# BB2D register map
Vendor: Texas Instruments
Peripheral module from a debugger description file (folder DRA74xP_75xP_76xP_77xP).
Registers are 32-bit, read-only, reset 0x0 unless marked. A register's access mark holds for its fields unless they carry their own. Offsets are as the file gives them; lines under a group give offsets from that group; [hi:lo] are bit positions; {n}, {i} and the like mark numbered series; 'fields as' and 'values as' point back to an identical list; <NAME> marks a mode.

## BB2D
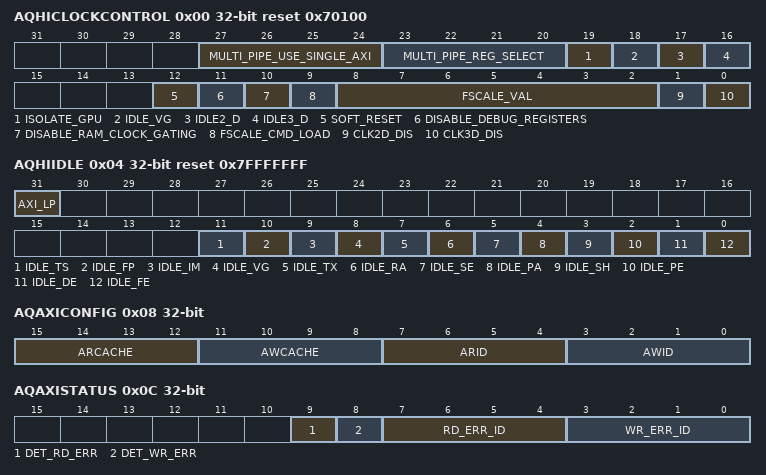
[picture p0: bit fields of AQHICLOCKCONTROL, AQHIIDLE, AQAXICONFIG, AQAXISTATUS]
0x00 AQHICLOCKCONTROL access per field reset 0x70100 — Clock control register.
  [27:24] MULTI_PIPE_USE_SINGLE_AXI rw — Force all the transactions to go to one AXI
  [23:20] MULTI_PIPE_REG_SELECT rw — Determines which HI/MC to use while reading registers
  [19] ISOLATE_GPU rw — Isolate GPU bit
  [18] IDLE_VG ro — VG pipe is idle
  [17] IDLE2_D ro — 2D pipe is idle
  [16] IDLE3_D ro — 3D pipe is idle
  [12] SOFT_RESET rw — Soft resets the subsystem
  [11] DISABLE_DEBUG_REGISTERS rw — Disable debug registers. If this bit is 1, debug registers are clock gated
  [10] DISABLE_RAM_CLOCK_GATING rw — Disables clock gating for RAMs
  [9] FSCALE_CMD_LOAD rw
  [8:2] FSCALE_VAL rw
  [1] CLK2D_DIS rw — Disable 2D clock
  [0] CLK3D_DIS rw — Disable 3D clock
0x04 AQHIIDLE reset 0x7FFFFFFF — Idle status register.
  [31] AXI_LP — AXI is in low power mode
  [11] IDLE_TS — TS is idle
  [10] IDLE_FP — FP is idle
  [9] IDLE_IM — IM is idle
  [8] IDLE_VG — VG is idle
  [7] IDLE_TX — TX is idle
  [6] IDLE_RA — RA is idle
  [5] IDLE_SE — SE is idle
  [4] IDLE_PA — PA is idle
  [3] IDLE_SH — SH is idle
  [2] IDLE_PE — PE is idle
  [1] IDLE_DE — DE is idle
  [0] IDLE_FE — FE is idle
0x08 AQAXICONFIG access per field — AXI config
  [15:12] ARCACHE rw, [11:8] AWCACHE rw, [7:4] ARID rw, [3:0] AWID rw
0x0C AQAXISTATUS — AXI status
  [9] DET_RD_ERR, [8] DET_WR_ERR, [7:4] RD_ERR_ID, [3:0] WR_ERR_ID
0x10 AQINTRACKNOWLEDGE — Interrupt acknowledge register. Each bit represents a corresponding event being triggered. Reading from this register clears the outstanding interrupt.
  [31:0] INTR_VEC
0x14 AQINTRENBL rw — Interrupt enable register. Each bit enables a corresponding event.
  [31:0] INTR_ENBL_VEC
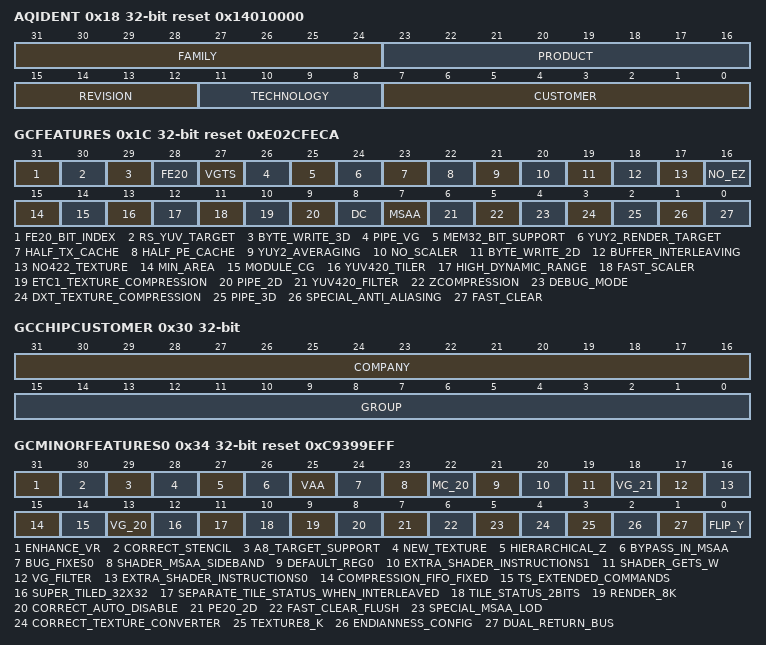
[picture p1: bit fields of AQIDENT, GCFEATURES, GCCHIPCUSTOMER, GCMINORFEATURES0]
0x18 AQIDENT reset 0x14010000 — Identification register.
  [31:24] FAMILY — Family value 0x1: GC500 0x2: GC520 0x3: GC530 0x4: GC400 0x5: GC450 0x8: GC600 0x9: GC700 0xA: GC350 0xB: GC380 0xC: GC800 0x10: GC1000 0x14: GC2000
  [23:16] PRODUCT — Product value
  [15:12] REVISION — Revision value
  [11:8] TECHNOLOGY — Technology value
  [7:0] CUSTOMER — Customer value
0x1C GCFEATURES reset 0xE02CFECA — Shows which features are enabled in current subsystem implementation. 0 : NONE 1 : AVAILABLE
  [31] FE20_BIT_INDEX — Supports 20 bit index.
  [30] RS_YUV_TARGET — Supports resolveing into YUV target.
  [29] BYTE_WRITE_3D — 3D PE has byte write capability.
  [28] FE20 — FE 2.0 is present.
  [27] VGTS — VG tesselator is present.
  [26] PIPE_VG — VG pipe is present.
  [25] MEM32_BIT_SUPPORT — 32 bit memory address support.
  [24] YUY2_RENDER_TARGET — YUY2 support in PE and YUY2 to RGB conversion in resolve.
  [23] HALF_TX_CACHE — TX cache is half.
  [22] HALF_PE_CACHE — PE cache is half.
  [21] YUY2_AVERAGING — YUY2 averaging support in resolve.
  [20] NO_SCALER — No 2D scaler.
  [19] BYTE_WRITE_2D — Supports byte write in 2D.
  [18] BUFFER_INTERLEAVING — Supports interleaving depth and color buffers.
  [17] NO422_TEXTURE — No 422 texture input format.
  [16] NO_EZ — No early-Z.
  [15] MIN_AREA — Configured to have minimum area.
  [14] MODULE_CG — Second level clock gating is available.
  [13] YUV420_TILER — YUV 4:2:0 tiler is available.
  [12] HIGH_DYNAMIC_RANGE — Shows if there is HDR support.
  [11] FAST_SCALER — Shows if there is HD scaler.
  [10] ETC1_TEXTURE_COMPRESSION
  [9] PIPE_2D — Shows if there is 2D engine.
  [8] DC — Shows if there is a display controller.
  [7] MSAA — MSAA support.
  [6] YUV420_FILTER — YUV 4:2:0 support in filter blit.
  [5] ZCOMPRESSION — Depth and color compression.
  [4] DEBUG_MODE — Debug registers.
  [3] DXT_TEXTURE_COMPRESSION
  [2] PIPE_3D — 3D pipe.
  [1] SPECIAL_ANTI_ALIASING — Full-screen anti-aliasing.
  [0] FAST_CLEAR
0x20 GCCHIPID reset 0x320 — Shows the ID for the subsystem in BCD.
  [31:0] ID — Subsystem ID in BCD
0x24 GCCHIPREV reset 0x5301 — Shows the revision for the subsystem in BCD.
  [31:0] REV — Revision in BCD
0x28 GCCHIPDATE reset 0x20111103 — Shows the release date for the subsystem.
  [31:0] DATE — Release date
0x2C GCCHIPTIME reset 0x140300 — Shows the release time for the subsystem.
  [31:0] TIME — Release time
0x30 GCCHIPCUSTOMER — Shows the customer and group for the subsystem.
  [31:16] COMPANY, [15:0] GROUP
0x34 GCMINORFEATURES0 reset 0xC9399EFF — Shows which minor features are enabled in the subsystem. 0 : NONE 1 : AVAILABLE
  [31] ENHANCE_VR — Enhance VR and add a mode to walk 16 pixels in 16-bit mode in vertical pass to improve cache hit rate when rotating 90/270.
  [30] CORRECT_STENCIL — Correct stencil behavior in depth only.
  [29] A8_TARGET_SUPPORT — 2D engine supports A8 target.
  [28] NEW_TEXTURE — New texture unit is available.
  [27] HIERARCHICAL_Z — Hierarchiccal Z is supported.
  [26] BYPASS_IN_MSAA — Shader supports bypass mode when MSAA is enabled.
  [25] VAA — VAA is available or not.
  [24] BUG_FIXES0
  [23] SHADER_MSAA_SIDEBAND — Put the MSAA data into sideband fifo.
  [22] MC_20 — New style MC with separate paths for color and depth.
  [21] DEFAULT_REG0 — Unavailable registers will return 0.
  [20] EXTRA_SHADER_INSTRUCTIONS1 — Sqrt, sin, cos instructions are available.
  [19] SHADER_GETS_W — W is sent to SH from RA.
  [18] VG_21 — Minor updates to VG pipe (Event generation from VG, TS, PE). Tiled image support.
  [17] VG_FILTER — VG filter is available.
  [16] EXTRA_SHADER_INSTRUCTIONS0 — Floor, ceil, and sign instructions are available.
  [15] COMPRESSION_FIFO_FIXED — If this bit is not set, the FIFO counter should be set to 50. Else, the default should remain.
  [14] TS_EXTENDED_COMMANDS — New commands added to the tessellator.
  [13] VG_20 — Major updates to VG pipe (TS buffer tiling. State masking.).
  [12] SUPER_TILED_32X32 — 32 × 32 super tile is available.
  [11] SEPARATE_TILE_STATUS_WHEN_INTERLEAVED — Use 2 separate tile status buffers in interleaved mode.
  [10] TILE_STATUS_2BITS — 2 bits are used instead of 4 bits for tile status.
  [9] RENDER_8K — Supports 8K render target.
  [8] CORRECT_AUTO_DISABLE — Reserved.
  [7] PE20_2D — 2D PE 2.0 is present.
  [6] FAST_CLEAR_FLUSH — Proper flush is done in fast clear cache.
  [5] SPECIAL_MSAA_LOD — Special LOD calculation when MSAA is on.
  [4] CORRECT_TEXTURE_CONVERTER — Driver hack is not needed.
  [3] TEXTURE8_K — Supports 8K × 8K textures.
  [2] ENDIANNESS_CONFIG — Configurable endianness support.
  [1] DUAL_RETURN_BUS — Dual Return Bus from HI to clients.
  [0] FLIP_Y — Y flipping capability is added to resolve.
0x3C GCRESETMEMCOUNTERS wo reset 0xC9399EFF — Writing 1 will reset the counters and stop counting. Write 0 to start counting again.
  [0] RESET — 1: reset the counters and stop counting 0: start counting
0x40 GCTOTALREADS — Total reads in terms of 64 bits.
  [31:0] COUNT — Total reads in terms of 64 bits
0x44 GCTOTALWRITES — Total writes in terms of 64 bits.
  [31:0] COUNT — Total writes in terms of 64 bits
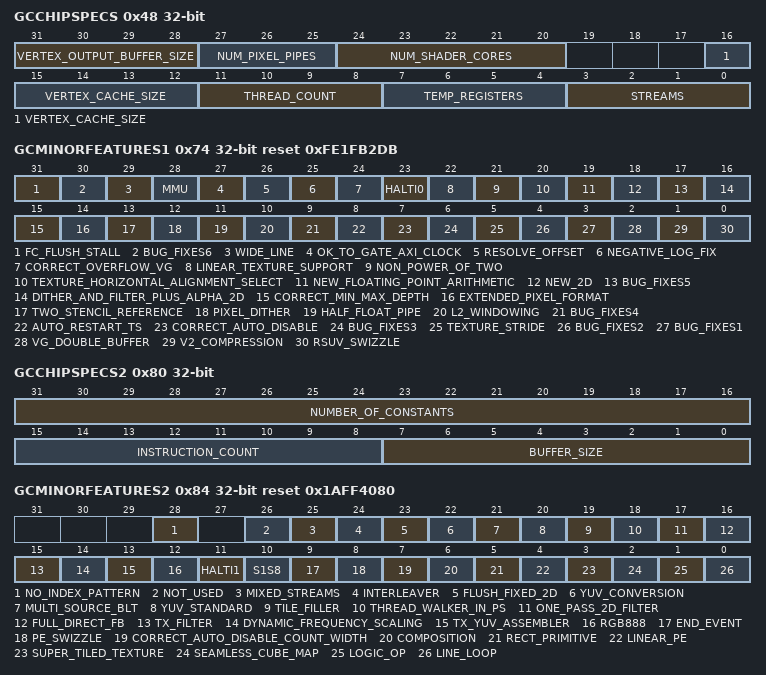
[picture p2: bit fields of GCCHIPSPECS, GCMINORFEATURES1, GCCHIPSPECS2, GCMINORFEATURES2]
0x48 GCCHIPSPECS — Specs for the subsystem.
  [31:28] VERTEX_OUTPUT_BUFFER_SIZE, [27:25] NUM_PIXEL_PIPES, [24:20] NUM_SHADER_CORES, [16:12] VERTEX_CACHE_SIZE, [11:8] THREAD_COUNT, [7:4] TEMP_REGISTERS, [3:0] STREAMS
0x4C GCTOTALWRITEBURSTS — Total write data count in terms of 64 bits.
  [31:0] COUNT — Total write data count in terms of 64 bits
0x50 GCTOTALWRITEREQS — Total write request count.
  [31:0] COUNT — Total write request count
0x54 GCTOTALWRITELASTS — Total WLAST count. This is used to match with
  [31:0] COUNT — Total WLAST count
0x58 GCTOTALREADBURSTS — Total read data count in terms of 64 bits.
  [31:0] COUNT — Total read data count in terms of 64 bits
0x5C GCTOTALREADREQS — Total read request count.
  [31:0] COUNT — Total read request count
0x60 GCTOTALREADLASTS — Total RLAST count. This is used to match with
  [31:0] COUNT — Total RLAST count
0x64 GCGPOUT0 rw — General purpose output register.
  [0] GCHOLD — 1 : Low power mode
0x70 GCAXICONTROL access per field — Special handling on AXI Bus
  [0] WR_FULL_BURST_MODE rw — 0: NO_BURST_RESET_VALUE 1: BURST_RESET_VALUE
0x74 GCMINORFEATURES1 reset 0xFE1FB2DB — Shows which features are enabled in the subsystem. 0 : NONE 1 : AVAILABLE
  [31] FC_FLUSH_STALL
  [30] BUG_FIXES6
  [29] WIDE_LINE
  [28] MMU
  [27] OK_TO_GATE_AXI_CLOCK
  [26] RESOLVE_OFFSET
  [25] NEGATIVE_LOG_FIX
  [24] CORRECT_OVERFLOW_VG
  [23] HALTI0
  [22] LINEAR_TEXTURE_SUPPORT
  [21] NON_POWER_OF_TWO
  [20] TEXTURE_HORIZONTAL_ALIGNMENT_SELECT
  [19] NEW_FLOATING_POINT_ARITHMETIC
  [18] NEW_2D
  [17] BUG_FIXES5
  [16] DITHER_AND_FILTER_PLUS_ALPHA_2D — Dither and filter+alpha available.
  [15] CORRECT_MIN_MAX_DEPTH — EEZ and HZ are correct.
  [14] EXTENDED_PIXEL_FORMAT
  [13] TWO_STENCIL_REFERENCE
  [12] PIXEL_DITHER
  [11] HALF_FLOAT_PIPE
  [10] L2_WINDOWING
  [9] BUG_FIXES4
  [8] AUTO_RESTART_TS
  [7] CORRECT_AUTO_DISABLE
  [6] BUG_FIXES3
  [5] TEXTURE_STRIDE — Texture has stride and memory addressing.
  [4] BUG_FIXES2
  [3] BUG_FIXES1
  [2] VG_DOUBLE_BUFFER — Double buffering support for VG (second TS--&gt;VG semaphore is present).
  [1] V2_COMPRESSION
  [0] RSUV_SWIZZLE — Resolve UV swizzle.
0x78 GCTOTALCYCLES rw reset 0x1DE2 — Total cycles. This register is a free running counter. It can be reset by writing 0 to it.
  [31:0] CYCLES — Total cycles
0x7C GCTOTALIDLECYCLES rw reset 0x1E08 — Total cycles where the GPU is idle. It is reset when register is written to. It looks at all the blocks but FE when determining the subsystem is idle.
  [31:0] CYCLES — Total cycles where the GPU is idle
0x80 GCCHIPSPECS2 — Specs for the subsystem
  [31:16] NUMBER_OF_CONSTANTS, [15:8] INSTRUCTION_COUNT, [7:0] BUFFER_SIZE
0x84 GCMINORFEATURES2 reset 0x1AFF4080 — Shows which features are enabled in the subsystem 0 : NONE 1 : AVAILABLE
  [28] NO_INDEX_PATTERN, [26] NOT_USED, [25] MIXED_STREAMS, [24] INTERLEAVER, [23] FLUSH_FIXED_2D, [22] YUV_CONVERSION, [21] MULTI_SOURCE_BLT, [20] YUV_STANDARD, [19] TILE_FILLER, [18] THREAD_WALKER_IN_PS, [17] ONE_PASS_2D_FILTER, [16] FULL_DIRECT_FB, [15] TX_FILTER, [14] DYNAMIC_FREQUENCY_SCALING, [13] TX_YUV_ASSEMBLER, [12] RGB888, [11] HALTI1, [10] S1S8, [9] END_EVENT, [8] PE_SWIZZLE, [7] CORRECT_AUTO_DISABLE_COUNT_WIDTH, [6] COMPOSITION, [5] RECT_PRIMITIVE, [4] LINEAR_PE, [3] SUPER_TILED_TEXTURE, [2] SEAMLESS_CUBE_MAP, [1] LOGIC_OP, [0] LINE_LOOP
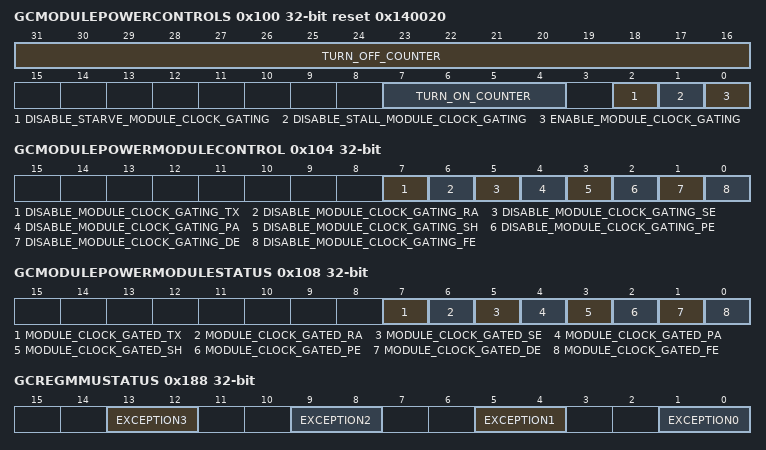
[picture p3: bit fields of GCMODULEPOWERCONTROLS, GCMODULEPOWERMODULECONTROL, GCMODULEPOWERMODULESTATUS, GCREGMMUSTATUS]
0x100 GCMODULEPOWERCONTROLS access per field reset 0x140020 — Control register for module level power controls.
  [31:16] TURN_OFF_COUNTER rw — Counter value for clock gating the module if the module is idle for this amount of clock cycles
  [7:4] TURN_ON_COUNTER rw — Number of clock cycles to wait after turning on the clock
  [2] DISABLE_STARVE_MODULE_CLOCK_GATING rw — Disables module level clock gating for starve/idle condition
  [1] DISABLE_STALL_MODULE_CLOCK_GATING rw — Disables module level clock gating for stall condition
  [0] ENABLE_MODULE_CLOCK_GATING rw — Enables module level clock gating
0x104 GCMODULEPOWERMODULECONTROL access per field — Module level control registers.
  [7] DISABLE_MODULE_CLOCK_GATING_TX rw — Disables module level clock gating for starve/idle condition
  [6] DISABLE_MODULE_CLOCK_GATING_RA rw — Disables module level clock gating for stall condition
  [5] DISABLE_MODULE_CLOCK_GATING_SE rw — Enables module level clock gating
  [4] DISABLE_MODULE_CLOCK_GATING_PA rw — Counter value for clock gating the module if the module is idle for this amount of clock cycles
  [3] DISABLE_MODULE_CLOCK_GATING_SH rw — Number of clock cycles to wait after turning on the clock
  [2] DISABLE_MODULE_CLOCK_GATING_PE rw — Disables module level clock gating for starve/idle condition
  [1] DISABLE_MODULE_CLOCK_GATING_DE rw — Disables module level clock gating for stall condition
  [0] DISABLE_MODULE_CLOCK_GATING_FE rw — Enables module level clock gating
0x108 GCMODULEPOWERMODULESTATUS — Module level control status
  [7] MODULE_CLOCK_GATED_TX — Module level clock gating is ON for TX
  [6] MODULE_CLOCK_GATED_RA — Module level clock gating is ON for RA
  [5] MODULE_CLOCK_GATED_SE — Module level clock gating is ON for SE
  [4] MODULE_CLOCK_GATED_PA — Module level clock gating is ON for PA
  [3] MODULE_CLOCK_GATED_SH — Module level clock gating is ON for SH
  [2] MODULE_CLOCK_GATED_PE — Module level clock gating is ON for PE
  [1] MODULE_CLOCK_GATED_DE — Module level clock gating is ON for DE
  [0] MODULE_CLOCK_GATED_FE — Module level clock gating is ON for FE
0x188 GCREGMMUSTATUS — Status register that holds which MMU generated an exception
  [13:12] EXCEPTION3 — MMU 3 caused an exception and theGCREGMMUEXCEPTION3 register holds the offending address. 0x1: SLAVE_NOT_PRESENT 0x2: PAGE_NOT_PRESENT 0x3: WRITE_VIOLATION
  [9:8] EXCEPTION2 — MMU 2 caused an exception and theGCREGMMUEXCEPTION2 register holds the offending address. 0x1: SLAVE_NOT_PRESENT 0x2: PAGE_NOT_PRESENT 0x3: WRITE_VIOLATION
  [5:4] EXCEPTION1 — MMU 1 caused an exception and theGCREGMMUEXCEPTION1 register holds the offending address. 0x1: SLAVE_NOT_PRESENT 0x2: PAGE_NOT_PRESENT 0x3: WRITE_VIOLATION
  [1:0] EXCEPTION0 — MMU 0 caused an exception and theGCREGMMUEXCEPTION0 holds the offending address: 0x1: SLAVE_NOT_PRESENT 0x2: PAGE_NOT_PRESENT 0x3: WRITE_VIOLATION
0x18C GCREGMMUCONTROL wo — Control register that enables the MMU (one time shot).
  [0] ENABLE — Enable the MMU. For security reasons, once the MMU is enabled it cannot be disabled until reset.
{0x190+4i} GCREGMMUEXCEPTION{i} rw (i=0..3) — Holds the original address that generated an exception
  [31:0] ADDRESS — The original address that generated an exception
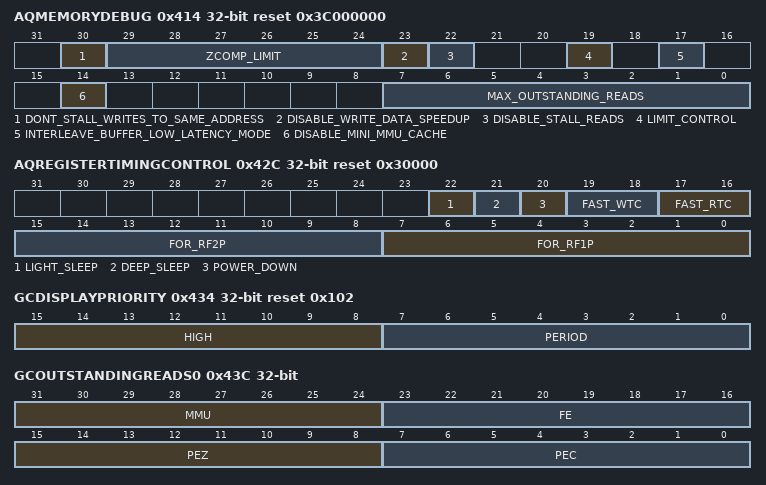
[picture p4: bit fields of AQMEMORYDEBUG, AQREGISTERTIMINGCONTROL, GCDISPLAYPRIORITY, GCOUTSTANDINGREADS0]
0x414 AQMEMORYDEBUG access per field reset 0x3C000000
  [30] DONT_STALL_WRITES_TO_SAME_ADDRESS rw
  [29:24] ZCOMP_LIMIT rw
  [23] DISABLE_WRITE_DATA_SPEEDUP rw
  [22] DISABLE_STALL_READS rw
  [19] LIMIT_CONTROL rw — Limit control 0: REQUESTS 1: DATA
  [17] INTERLEAVE_BUFFER_LOW_LATENCY_MODE rw
  [14] DISABLE_MINI_MMU_CACHE rw
  [7:0] MAX_OUTSTANDING_READS rw — Limits the total number of outstanding read requests.
0x42C AQREGISTERTIMINGCONTROL rw reset 0x30000
  [22] LIGHT_SLEEP
  [21] DEEP_SLEEP
  [20] POWER_DOWN — Powerdown memory
  [19:18] FAST_WTC — WTC for fast RAMs
  [17:16] FAST_RTC — RTC for fast RAMs
  [15:8] FOR_RF2P
  [7:0] FOR_RF1P
0x434 GCDISPLAYPRIORITY access per field reset 0x102 — Controls the priority of the display controller requests. This works like a PWM. One register gives the period, and the other gives the ON time. When PWM is ON, display requests are accepted if both display and the other request is valid. If it is OFF, the other request will be accepted. If only one request is valid, it takes the bus regardless of the PWM bit.
  [15:8] HIGH rw — 'Duty cycle'
  [7:0] PERIOD rw
0x438 GCDBGCYCLECOUNTER rw reset 0x1C5E — Increments every cycle.
  [31:0] COUNT — Increments every cycle
0x43C GCOUTSTANDINGREADS0 — Number of outstanding reads per client in multiples of 8 bytes.
  [31:24] MMU — Number of outstanding MMU reads in multiples of 8 bytes
  [23:16] FE — Number of outstanding FE reads in multiples of 8 bytes
  [15:8] PEZ — Number of outstanding PEZ reads in multiples of 8 bytes
  [7:0] PEC — Number of outstanding PEC reads in multiples of 8 bytes
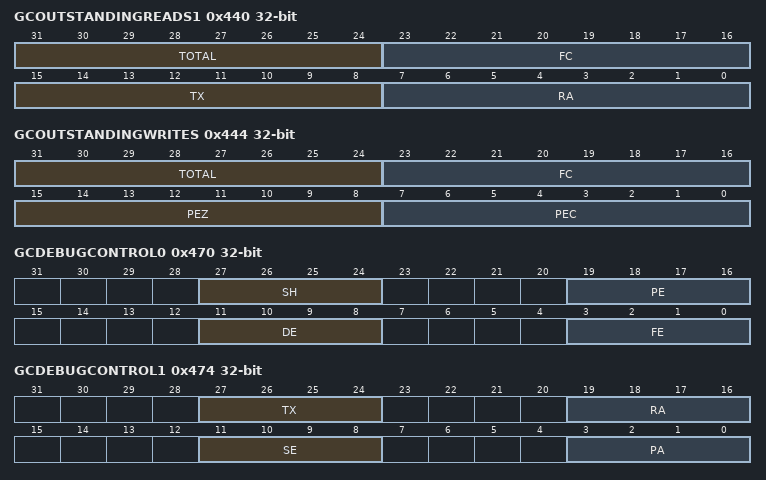
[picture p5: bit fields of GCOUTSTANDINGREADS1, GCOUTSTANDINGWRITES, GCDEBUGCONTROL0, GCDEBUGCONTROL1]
0x440 GCOUTSTANDINGREADS1 — Number of outstanding reads per client in multiples of 8 bytes.
  [31:24] TOTAL — This field keeps the value of total read requests or total requested data (in 64 bits) depending on the value ofAQMEMORYDEBUG[19] LIMIT_CONTROL register field.
  [23:16] FC — Number of outstanding FC reads in multiples of 8 bytes
  [15:8] TX — Number of outstanding TX reads in multiples of 8 bytes
  [7:0] RA — Number of outstanding RA reads in multiples of 8 bytes
0x444 GCOUTSTANDINGWRITES — Number of outstanding writes per client.
  [31:24] TOTAL — This field keeps the value of total write requests or total requested data (in 64 bits) depending on the value ofAQMEMORYDEBUG[19] LIMIT_CONTROL register field.
  [23:16] FC — Number of outstanding FC writes in multiples of 8 bytes
  [15:8] PEZ — Number of outstanding PEZ writes in multiples of 8 bytes
  [7:0] PEC — Number of outstanding PEC writes in multiples of 8 bytes
0x448 GCDEBUGSIGNALSRA — 32 bit debug signal from RA.
  [31:0] SIGNAL — Signals according toGCDEBUGCONTROL1[19:16] RA: 0x0: Valid pixel count. 0x1: Total quad count (after EEZ). 0x2: Valid quad count (after EZ and EEZ). 0x3: Total primitive count. 0x4: Various signals from input stage. See GC320 spec for details. 0x5: Various signals from input stage. See GC320 spec for details. 0x6: Various signals from render pipe. See GC320 spec for details. 0x7: Various signals from render cache. See GC320 spec for details. 0x8: Various signals from raster engine. See GC320 spec for details. 0x9: Cache miss count (in the pipeline). 0xA: Cache miss count (in the prefetcher). 0xB: EEZ culled quads. 0xF: Signature = 0x12344321.
0x44C GCDEBUGSIGNALSTX — 32 bit debug signal from TX.
  [31:0] SIGNAL — Signals according toGCDEBUGCONTROL1[27:24] TX : 0x0: Total bilinear texture requests. 0x1: Total trilinear texture requests. 0x2: Total discarded texture requests. 0x3: Total texture requests. 0x4: Various signals from input stage. See GC320 spec for details. 0x5: Memory read count. 0x6: Memory read count in 8B. 0x7: Cache miss count (in the pipeline). 0x8: Total hitting texels (in pre-fetcher). 0x9: Total missing texels (in pre-fetcher). 0xF: Signature = 0x12211221.
0x450 GCDEBUGSIGNALSFE — 32 bit debug signal from FE.
  [31:0] SIGNAL
0x454 GCDEBUGSIGNALSPE — 32 bit debug signal from PE.
  [31:0] SIGNAL — Signals according toGCDEBUGCONTROL0[19:16] PE: 0x0: pixel count killed by color pipe 0x1: pixel count killed by depth pipe 0x2: pixel count drawn by color pipe 0x3: pixel count drawn by depth pipe 0x4: debug signals for 3d_io, 2d_filter, 2d_fsm 0x5: debug signals for cache2d_cntrl 0x6: debug signals for cache2d_tag_alloc 0x7: debug signals for cache3d_c_cntrl, cache3d_c_tag_alloc 0x8: debug signals for cache3d_z_cntrl, cache3d_z_tag_alloc 0x9: debug signals for pref_2d, pref_3d 0xA : debug signals for cmd_state 0xB: 2d pixel count drawn by 2d pipe 0xF: Signature = 0xBABEF00D.
0x458 GCDEBUGSIGNALSDE — 32 bit debug signal from DE.
  [31:0] SIGNAL
0x45C GCDEBUGSIGNALSSH — 32 bit debug signal from SH.
  [31:0] SIGNAL — Signals according toGCDEBUGCONTROL0[27:24] SH. Please refer to GC320 spec for bit position information for all the signals 0x0 : interface signals for debug 0x1 : Instruction Sequencing and vertex input state machine 0x2 : vertex input/output buffer full/empty. Context PC. Physical page valid 0x3 : vertex/pixel, output attribute counts. Some interface signals 0x4 : Shader cycle count, for determining the shader clock 0x5 : Current pixel XY value 0x6 : Last pixels XY value 0x7 : Total pixel instructions executed 0x8 : Total pixels shaded 0x9 : Total vertex instructions executed 0xA : Total vertices shaded 0xB : Total vertex branch instructions 0xC : Total vertex texture instructions 0xD : Total pixel branch instructions 0xE : Total pixel texture instructions 0xF : Reserved signature 0xDEADBEEF
0x460 GCDEBUGSIGNALSPA — 32 bit debug signal from PA.
  [31:0] SIGNAL — Signals according toGCDEBUGCONTROL1[3:0] PA: 0x0: Various signals from input stage. See GC320 spec for details. 0x1: Various signals from input stage. See GC320 spec for details. 0x2: Various signals from input stage. See GC320 spec for details. 0x3: total vertex count 0x4: input primitive count 0x5: output primitive count 0x6: depth clipped primitive count 0x7: trivial rejected primitive count 0x8: culled primitive count 0xF: Signature = 0x0000AAAA
0x464 GCDEBUGSIGNALSSE — 32 bit debug signal from SE.
  [31:0] SIGNAL — Signals according toGCDEBUGCONTROL1[11:8] SE: 0x0: culled triangles count. 0x1: culled lines count. 0x2: [31:18] goto signals, [17:8] main state machine state, [7:0] output state machine state. See GC320 spec for details. 0x3: [31:22] unused, [21] early_isTriangle, [20] isTriangle, [19] increment_pc_e0, [18:14] jump_to_signals. See GC320 spec for details. [13:12] max_x_p_e2, [11:10] mid_x_p_e2, [9:8] min_x_p_e2, [7:6] max_y_p_e2, [5:4] mid_y_p_e2. See GC320 spec for details. [3:2] min_y_p_e2, [1:0] min_z_p_e2. See GC320 spec for details. 0x4: area_e2. See GC320 spec for details. 0x5: x0_e2. See GC320 spec for details. 0x6: x1_e2. See GC320 spec for details. 0x7: x2_e2. See GC320 spec for details. 0x8: y0_e2. See GC320 spec for details. 0x9: y1_e2. See GC320 spec for details. 0xA: y2_e2. See GC320 spec for details. 0xB: init_y_e2. See GC320 spec for details. 0xC: init_y_e2. See GC320 spec for details. 0xD: y2_e2. See GC320 spec for details. 0xE: y2_e2. See GC320 spec for details. 0xF: Signature = 0x5E5E5E5E.
0x468 GCDEBUGSIGNALSMC — 32 bit debug signal from MC.
  [31:0] SIGNAL — Signals according toGCDEBUGCONTROL2[3:0] MC: 0x0: Various signals from FC block. See GC320 spec for details. 0x1: Total read req in terms of 8B from pipeline. 0x2: Total read req in terms of 8B sent out from the subsystem. 0x3: Total write req in terms of 8B from pipeline. 0xF: Signature = 0x12345678.
0x46C GCDEBUGSIGNALSHI — 32 bit debug signal from HI.
  [31:0] SIGNAL — Signals according toGCDEBUGCONTROL2[11:8] HI: 0x0: Number of cycles AXI read request is stalled. 0x1: Number of cycles AXI write request is stalled. 0x2: Number of cycles AXI write data is stalled. 0xF: Signature = 0xAAAAAAAA
0x470 GCDEBUGCONTROL0 access per field
  [27:24] SH rw — Selects which set of 32 bit data to get from SH. Resets the counters if set to 0xF
  [19:16] PE rw — Selects which set of 32 bit data to get from PE. Resets the counters if set to 0xF
  [11:8] DE rw — Selects which set of 32 bit data to get from DE. Resets the counters if set to 0xF
  [3:0] FE rw — Selects which set of 32 bit data to get from FE. Resets the counters if set to 0xF
0x474 GCDEBUGCONTROL1 access per field
  [27:24] TX rw — Selects which set of 32 bit data to get from TX. Resets the counters if set to 0xF
  [19:16] RA rw — Selects which set of 32 bit data to get from RA. Resets the counters if set to 0xF
  [11:8] SE rw — Selects which set of 32 bit data to get from SE. Resets the counters if set to 0xF
  [3:0] PA rw — Selects which set of 32 bit data to get from PA. Resets the counters if set to 0xF
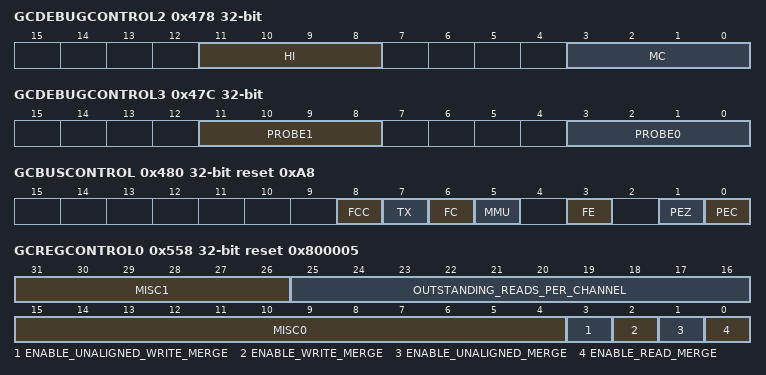
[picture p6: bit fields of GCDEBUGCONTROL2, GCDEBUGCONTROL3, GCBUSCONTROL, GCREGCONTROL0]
0x478 GCDEBUGCONTROL2 access per field
  [11:8] HI rw — Selects which set of 32 bit data to get from HI. Resets the counters if set to 0xF
  [3:0] MC rw — Selects which set of 32 bit data to get from MC. Resets the counters if set to 0xF
0x47C GCDEBUGCONTROL3 access per field
  [11:8] PROBE1 rw — Selects which module's output will be put in the MSB 32 bits of 64 bit debug signal. 0x0: FE 0x1: DE 0x2: PE 0x3: SH 0x4: PA 0x5: SE 0x6: RA 0x7: TX 0x8: MC
  [3:0] PROBE0 rw — Selects which module's output will be put in the LSB 32 bits of 64 bit debug signal. 0x0: FE 0x1: DE 0x2: PE 0x3: SH 0x4: PA 0x5: SE 0x6: RA 0x7: TX 0x8: MC
0x480 GCBUSCONTROL access per field reset 0xA8 — Shows which features are enabled in the subsystem. 0 : NONE 1 : AVAILABLE
  [8] FCC rw — Select the return bus for FCC
  [7] TX rw — Select the return bus for TX
  [6] FC rw — Select the return bus for FC-Depth
  [5] MMU rw — Select the return bus for MMU
  [3] FE rw — Select the return bus for FE
  [1] PEZ rw — Select the return bus for PEZ
  [0] PEC rw — Select the return bus for PEC
0x484 GCREGENDIANNESS0 rw
  [31:0] WORD_SWAP — Flip the words of 32 bit data. 0x12345678 becomes 0x56781234
0x488 GCREGENDIANNESS1 rw
  [31:0] BYTE_SWAP — Flip the bytes of 16 bit data. 0x12345678 becomes 0x34127856
0x48C GCREGENDIANNESS2 rw
  [31:0] BIT_SWAP — Flip the bits of 8 bit data. 0x12345678 becomes 0x84C2A6E1
0x490 GCREGDRAWPRIMITIVESTARTTIMESTAMP
  [31:0] START_TIME — 32-bit timestamp when PE received draw_primitive_start command
0x494 GCREGDRAWPRIMITIVEENDTIMESTAMP
  [31:0] END_TIME — 32-bit timestamp when PE received draw_primitive_end command
0x558 GCREGCONTROL0 rw reset 0x800005 — Composition trigger.
  [31:26] MISC1, [25:16] OUTSTANDING_READS_PER_CHANNEL, [15:4] MISC0, [3] ENABLE_UNALIGNED_WRITE_MERGE, [2] ENABLE_WRITE_MERGE, [1] ENABLE_UNALIGNED_MERGE, [0] ENABLE_READ_MERGE
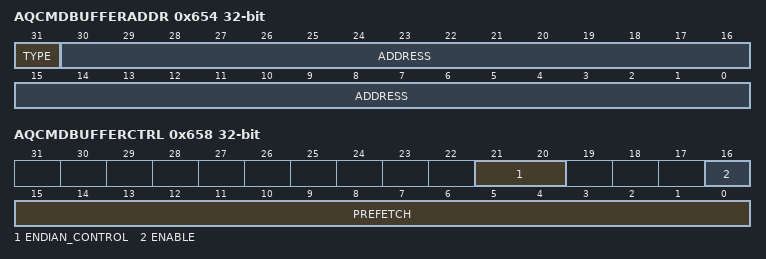
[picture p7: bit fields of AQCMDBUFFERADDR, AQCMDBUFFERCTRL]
0x654 AQCMDBUFFERADDR wo — Base address for the command buffer. The address must be 64-bit aligned and it is always physical. To use addresses above 0x8000_0000, program AQMemoryFE with the appropriate offset. Also, this register cannot be read. To check the value of the current fetch address use.
  [31] TYPE — 0: SYSTEM 1: VIRTUAL_SYSTEM
  [30:0] ADDRESS
0x658 AQCMDBUFFERCTRL wo — Command buffer control
  [21:20] ENDIAN_CONTROL — Endian control 0: NO_SWAP 1: SWAP_WORD 2: SWAP_DWORD
  [16] ENABLE — Command buffer 0: DISABLE 1: ENABLE
  [15:0] PREFETCH — Number of 64-bit words to fetch from the command buffer.
0x65C AQFESTATUS — FE status
  [0] COMMAND_DATA — Status of the command parser. 0: Idle 1: Busy
0x664 AQFEDEBUGCURCMDADR — This is the command decoder address. The address is always physical so the MSB should always be 0.
  [31:3] CUR_CMD_ADR
